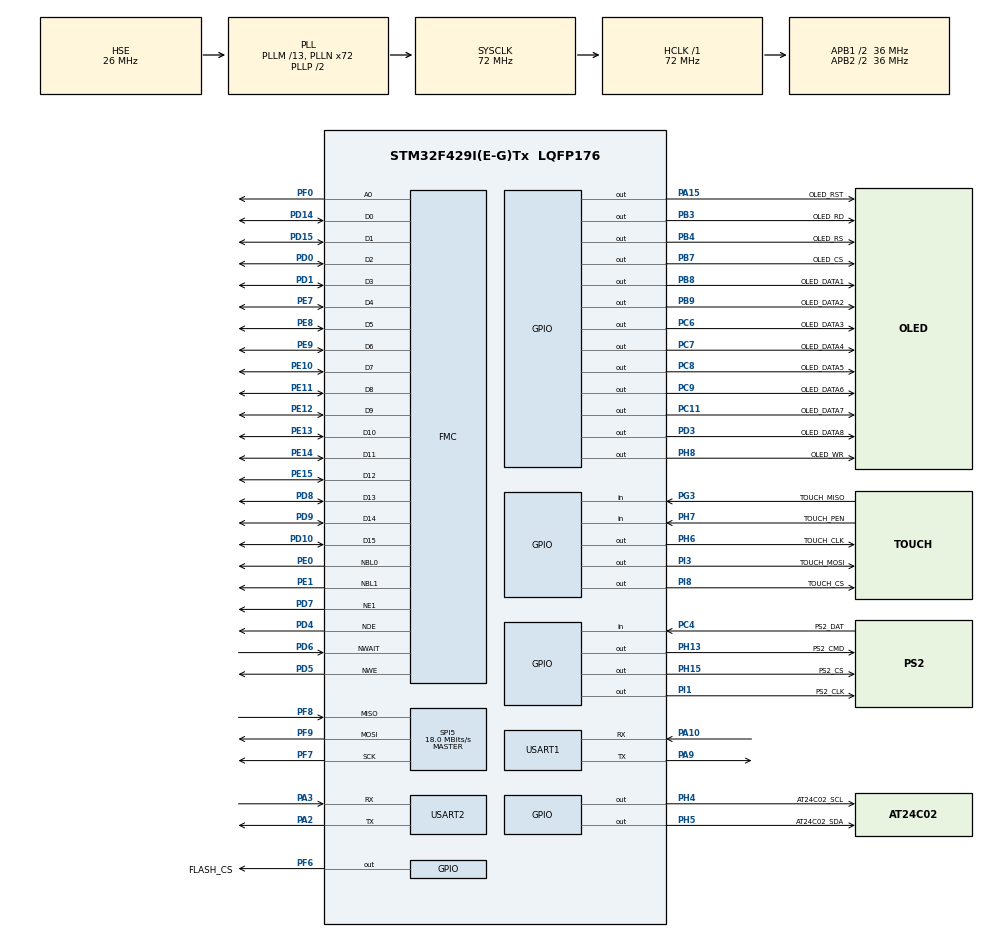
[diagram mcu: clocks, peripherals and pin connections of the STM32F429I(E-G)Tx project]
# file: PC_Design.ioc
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Dma.Request0=USART1_RX
Dma.Request1=USART1_TX
Dma.Request2=USART2_RX
Dma.Request3=USART2_TX
Dma.USART1_RX.0.Direction=DMA_PERIPH_TO_MEMORY
Dma.USART1_RX.0.FIFOMode=DMA_FIFOMODE_DISABLE
Dma.USART1_RX.0.Instance=DMA2_Stream2
Dma.USART1_RX.0.MemDataAlignment=DMA_MDATAALIGN_BYTE
Dma.USART1_RX.0.MemInc=DMA_MINC_ENABLE
Dma.USART1_RX.0.Mode=DMA_NORMAL
Dma.USART1_RX.0.PeriphDataAlignment=DMA_PDATAALIGN_BYTE
Dma.USART1_RX.0.PeriphInc=DMA_PINC_DISABLE
Dma.USART1_RX.0.Priority=DMA_PRIORITY_LOW
Dma.USART1_TX.1.Direction=DMA_MEMORY_TO_PERIPH
Dma.USART1_TX.1.FIFOMode=DMA_FIFOMODE_DISABLE
Dma.USART1_TX.1.Instance=DMA2_Stream7
Dma.USART1_TX.1.MemDataAlignment=DMA_MDATAALIGN_BYTE
Dma.USART1_TX.1.MemInc=DMA_MINC_ENABLE
Dma.USART1_TX.1.Mode=DMA_NORMAL
Dma.USART1_TX.1.PeriphDataAlignment=DMA_PDATAALIGN_BYTE
Dma.USART1_TX.1.PeriphInc=DMA_PINC_DISABLE
Dma.USART1_TX.1.Priority=DMA_PRIORITY_LOW
Dma.USART2_RX.2.Direction=DMA_PERIPH_TO_MEMORY
Dma.USART2_RX.2.FIFOMode=DMA_FIFOMODE_DISABLE
Dma.USART2_RX.2.Instance=DMA1_Stream5
Dma.USART2_RX.2.MemDataAlignment=DMA_MDATAALIGN_BYTE
Dma.USART2_RX.2.MemInc=DMA_MINC_ENABLE
Dma.USART2_RX.2.Mode=DMA_NORMAL
Dma.USART2_RX.2.PeriphDataAlignment=DMA_PDATAALIGN_BYTE
Dma.USART2_RX.2.PeriphInc=DMA_PINC_DISABLE
Dma.USART2_RX.2.Priority=DMA_PRIORITY_LOW
Dma.USART2_TX.3.Direction=DMA_MEMORY_TO_PERIPH
Dma.USART2_TX.3.FIFOMode=DMA_FIFOMODE_DISABLE
Dma.USART2_TX.3.Instance=DMA1_Stream6
Dma.USART2_TX.3.MemDataAlignment=DMA_MDATAALIGN_BYTE
Dma.USART2_TX.3.MemInc=DMA_MINC_ENABLE
Dma.USART2_TX.3.Mode=DMA_NORMAL
Dma.USART2_TX.3.PeriphDataAlignment=DMA_PDATAALIGN_BYTE
Dma.USART2_TX.3.PeriphInc=DMA_PINC_DISABLE
Dma.USART2_TX.3.Priority=DMA_PRIORITY_LOW
FREERTOS.INCLUDE_vTaskDelayUntil=1
FREERTOS.Tasks01=defaultTask,0,128,StartDefaultTask,Default,NULL,Dynamic,NULL,NULL
FREERTOS.configMAX_PRIORITIES=9
Mcu.Family=STM32F4
Mcu.Name=STM32F429I(E-G)Tx
Mcu.Package=LQFP176
NVIC.DMA1_Stream5_IRQn=true\:0\:0\:false\:false\:true\:true\:false\:true
NVIC.DMA1_Stream6_IRQn=true\:0\:0\:false\:false\:true\:true\:false\:true
NVIC.DMA2_Stream2_IRQn=true\:0\:0\:false\:false\:true\:true\:false\:true
NVIC.DMA2_Stream7_IRQn=true\:0\:0\:false\:false\:true\:true\:false\:true
NVIC.PriorityGroup=NVIC_PRIORITYGROUP_4
NVIC.TIM5_IRQn=true\:0\:0\:false\:false\:true\:true\:true\:true
NVIC.TIM7_IRQn=true\:0\:0\:false\:false\:true\:false\:false\:true
NVIC.TimeBase=TIM7_IRQn
NVIC.TimeBaseIP=TIM7
NVIC.USART1_IRQn=true\:5\:0\:true\:false\:true\:false\:true\:true
NVIC.USART2_IRQn=true\:5\:0\:true\:false\:true\:false\:true\:true
PA10.Mode=Asynchronous
PA10.Signal=USART1_RX
PA13.Mode=Serial_Wire
PA13.Signal=SYS_JTMS-SWDIO
PA14.Mode=Serial_Wire
PA14.Signal=SYS_JTCK-SWCLK
PA15.GPIO_Label=OLED_RST
PA15.GPIO_ModeDefaultOutputPP=GPIO_MODE_OUTPUT_PP
PA15.GPIO_PuPd=GPIO_PULLUP
PA15.GPIO_Speed=GPIO_SPEED_FREQ_HIGH
PA15.PinState=GPIO_PIN_RESET
PA15.Signal=GPIO_Output
PA2.Mode=Asynchronous
PA2.Signal=USART2_TX
PA3.Mode=Asynchronous
PA3.Signal=USART2_RX
PA9.Mode=Asynchronous
PA9.Signal=USART1_TX
PB3.GPIO_Label=OLED_RD
PB3.GPIO_PuPd=GPIO_PULLUP
PB3.GPIO_Speed=GPIO_SPEED_FREQ_HIGH
PB3.Signal=GPIO_Output
PB4.GPIO_Label=OLED_RS
PB4.GPIO_PuPd=GPIO_PULLUP
PB4.GPIO_Speed=GPIO_SPEED_FREQ_HIGH
PB4.Signal=GPIO_Output
PB7.GPIO_Label=OLED_CS
PB7.GPIO_PuPd=GPIO_PULLUP
PB7.GPIO_Speed=GPIO_SPEED_FREQ_HIGH
PB7.Signal=GPIO_Output
PB8.GPIO_Label=OLED_DATA1
PB8.GPIO_PuPd=GPIO_PULLUP
PB8.GPIO_Speed=GPIO_SPEED_FREQ_HIGH
PB8.Signal=GPIO_Output
PB9.GPIO_Label=OLED_DATA2
PB9.GPIO_PuPd=GPIO_PULLUP
PB9.GPIO_Speed=GPIO_SPEED_FREQ_HIGH
PB9.Signal=GPIO_Output
PC11.GPIO_Label=OLED_DATA7
PC11.GPIO_PuPd=GPIO_PULLUP
PC11.GPIO_Speed=GPIO_SPEED_FREQ_HIGH
PC11.Signal=GPIO_Output
PC4.GPIO_Label=PS2_DAT
PC4.GPIO_PuPd=GPIO_PULLDOWN
PC4.Signal=GPIO_Input
PC6.GPIO_Label=OLED_DATA3
PC6.GPIO_PuPd=GPIO_PULLUP
PC6.GPIO_Speed=GPIO_SPEED_FREQ_HIGH
PC6.Signal=GPIO_Output
PC7.GPIO_Label=OLED_DATA4
PC7.GPIO_PuPd=GPIO_PULLUP
PC7.GPIO_Speed=GPIO_SPEED_FREQ_HIGH
PC7.Signal=GPIO_Output
PC8.GPIO_Label=OLED_DATA5
PC8.GPIO_PuPd=GPIO_PULLUP
PC8.GPIO_Speed=GPIO_SPEED_FREQ_HIGH
PC8.Signal=GPIO_Output
PC9.GPIO_Label=OLED_DATA6
PC9.GPIO_PuPd=GPIO_PULLUP
PC9.GPIO_Speed=GPIO_SPEED_FREQ_HIGH
PC9.Signal=GPIO_Output
PD0.Signal=FMC_D2_DA2
PD1.Signal=FMC_D3_DA3
PD10.Signal=FMC_D15_DA15
PD14.Signal=FMC_D0_DA0
PD15.Signal=FMC_D1_DA1
PD3.GPIO_Label=OLED_DATA8
PD3.GPIO_PuPd=GPIO_PULLUP
PD3.GPIO_Speed=GPIO_SPEED_FREQ_HIGH
PD3.Signal=GPIO_Output
PD4.Signal=FMC_NOE
PD5.Signal=FMC_NWE
PD6.Signal=FMC_NWAIT
PD7.Mode=NorPsramChipSelect1_1
PD7.Signal=FMC_NE1
PD8.Signal=FMC_D13_DA13
PD9.Signal=FMC_D14_DA14
PE0.Signal=FMC_NBL0
PE1.Signal=FMC_NBL1
PE10.Signal=FMC_D7_DA7
PE11.Signal=FMC_D8_DA8
PE12.Signal=FMC_D9_DA9
PE13.Signal=FMC_D10_DA10
PE14.Signal=FMC_D11_DA11
PE15.Signal=FMC_D12_DA12
PE7.Signal=FMC_D4_DA4
PE8.Signal=FMC_D5_DA5
PE9.Signal=FMC_D6_DA6
PF0.Signal=FMC_A0
PF6.GPIO_Label=FLASH_CS
PF6.GPIO_Speed=GPIO_SPEED_FREQ_HIGH
PF6.Signal=GPIO_Output
PF7.Mode=Full_Duplex_Master
PF7.Signal=SPI5_SCK
PF8.Mode=Full_Duplex_Master
PF8.Signal=SPI5_MISO
PF9.Mode=Full_Duplex_Master
PF9.Signal=SPI5_MOSI
PG3.GPIO_Label=TOUCH_MISO
PG3.Signal=GPIO_Input
PH0/OSC_IN.Mode=HSE-External-Oscillator
PH0/OSC_IN.Signal=RCC_OSC_IN
PH1/OSC_OUT.Mode=HSE-External-Oscillator
PH1/OSC_OUT.Signal=RCC_OSC_OUT
PH13.GPIO_Label=PS2_CMD
PH13.Signal=GPIO_Output
PH15.GPIO_Label=PS2_CS
PH15.Signal=GPIO_Output
PH4.GPIO_Label=AT24C02_SCL
PH4.GPIO_PuPd=GPIO_PULLUP
PH4.GPIO_Speed=GPIO_SPEED_FREQ_HIGH
PH4.PinState=GPIO_PIN_SET
PH4.Signal=GPIO_Output
PH5.GPIO_Label=AT24C02_SDA
PH5.GPIO_PuPd=GPIO_PULLUP
PH5.GPIO_Speed=GPIO_SPEED_FREQ_HIGH
PH5.PinState=GPIO_PIN_SET
PH5.Signal=GPIO_Output
PH6.GPIO_Label=TOUCH_CLK
PH6.GPIO_PuPd=GPIO_PULLUP
PH6.GPIO_Speed=GPIO_SPEED_FREQ_HIGH
PH6.PinState=GPIO_PIN_RESET
PH6.Signal=GPIO_Output
PH7.GPIO_Label=TOUCH_PEN
PH7.Signal=GPIO_Input
PH8.GPIO_Label=OLED_WR
PH8.GPIO_PuPd=GPIO_PULLUP
PH8.GPIO_Speed=GPIO_SPEED_FREQ_HIGH
PH8.Signal=GPIO_Output
PI1.GPIO_Label=PS2_CLK
PI1.Signal=GPIO_Output
PI3.GPIO_Label=TOUCH_MOSI
PI3.GPIO_PuPd=GPIO_PULLUP
PI3.GPIO_Speed=GPIO_SPEED_FREQ_HIGH
PI3.Signal=GPIO_Output
PI8.GPIO_Label=TOUCH_CS
PI8.GPIO_ModeDefaultOutputPP=GPIO_MODE_OUTPUT_PP
PI8.GPIO_PuPd=GPIO_PULLUP
PI8.Signal=GPIO_Output
ProjectManager.HeapSize=0x200
ProjectManager.StackSize=0x400
ProjectManager.TargetToolchain=MDK-ARM V5.27
RCC.48MHZClocksFreq_Value=36000000
RCC.AHBFreq_Value=72000000
RCC.APB1CLKDivider=RCC_HCLK_DIV2
RCC.APB1Freq_Value=36000000
RCC.APB1TimFreq_Value=72000000
RCC.APB2CLKDivider=RCC_HCLK_DIV2
RCC.APB2Freq_Value=36000000
RCC.APB2TimFreq_Value=72000000
RCC.CortexFreq_Value=72000000
RCC.HCLKFreq_Value=72000000
RCC.HSE_VALUE=26000000
RCC.HSI_VALUE=16000000
RCC.LSE_VALUE=32768
RCC.PLLM=13
RCC.PLLN=72
RCC.PLLSourceVirtual=RCC_PLLSOURCE_HSE
RCC.SYSCLKFreq_VALUE=72000000
RCC.SYSCLKSource=RCC_SYSCLKSOURCE_PLLCLK
RCC.VCOOutputFreq_Value=144000000
SH.FMC_A0.0=FMC_A0,1b-a1
SH.FMC_D0_DA0.0=FMC_D0,16b-d1
SH.FMC_D10_DA10.0=FMC_D10,16b-d1
SH.FMC_D11_DA11.0=FMC_D11,16b-d1
SH.FMC_D12_DA12.0=FMC_D12,16b-d1
SH.FMC_D13_DA13.0=FMC_D13,16b-d1
SH.FMC_D14_DA14.0=FMC_D14,16b-d1
SH.FMC_D15_DA15.0=FMC_D15,16b-d1
SH.FMC_D1_DA1.0=FMC_D1,16b-d1
SH.FMC_D2_DA2.0=FMC_D2,16b-d1
SH.FMC_D3_DA3.0=FMC_D3,16b-d1
SH.FMC_D4_DA4.0=FMC_D4,16b-d1
SH.FMC_D5_DA5.0=FMC_D5,16b-d1
SH.FMC_D6_DA6.0=FMC_D6,16b-d1
SH.FMC_D7_DA7.0=FMC_D7,16b-d1
SH.FMC_D8_DA8.0=FMC_D8,16b-d1
SH.FMC_D9_DA9.0=FMC_D9,16b-d1
SH.FMC_NBL0.0=FMC_NBL0,2ByteEnable1
SH.FMC_NBL1.0=FMC_NBL1,2ByteEnable1
SH.FMC_NOE.0=FMC_NOE,Sram1
SH.FMC_NWAIT.0=FMC_NWAIT,AsynchronousWait1
SH.FMC_NWE.0=FMC_NWE,Sram1
SPI5.BaudRatePrescaler=SPI_BAUDRATEPRESCALER_2
SPI5.CLKPhase=SPI_PHASE_2EDGE
SPI5.CLKPolarity=SPI_POLARITY_HIGH
SPI5.CalculateBaudRate=18.0 MBits/s
SPI5.Direction=SPI_DIRECTION_2LINES
SPI5.Mode=SPI_MODE_MASTER
SPI5.VirtualType=VM_MASTER
TIM5.Prescaler=71
USART1.VirtualMode=VM_ASYNC
USART2.VirtualMode=VM_ASYNC
VP_FREERTOS_VS_CMSIS_V1.Mode=CMSIS_V1
VP_SYS_VS_tim7.Mode=TIM7
VP_TIM5_VS_ClockSourceINT.Mode=Internal
board=custom

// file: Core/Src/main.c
/* USER CODE BEGIN Header */
/**
  ******************************************************************************
  * @file           : main.c
  * @brief          : Main program body
  ******************************************************************************
  * @attention
  *
  * <h2><center>&copy; Copyright (c) 2021 STMicroelectronics.
  * All rights reserved.</center></h2>
  *
  * This software component is licensed by ST under BSD 3-Clause license,
  * the "License"; You may not use this file except in compliance with the
  * License. You may obtain a copy of the License at:
  *                        opensource.org/licenses/BSD-3-Clause
  *
  ******************************************************************************
  */
/* USER CODE END Header */
#include "main.h"
#include "cmsis_os.h"
#include "dma.h"
#include "spi.h"
#include "tim.h"
#include "usart.h"
#include "gpio.h"
#include "fmc.h"

/* USER CODE BEGIN Includes */
#include "System_Config.h"
/* USER CODE END Includes */

void SystemClock_Config(void);
void MX_FREERTOS_Init(void);

int main(void)
{

  /* MCU Configuration--------------------------------------------------------*/

  /* Reset of all peripherals, Initializes the Flash interface and the Systick. */
  HAL_Init();

  /* Configure the system clock */
  SystemClock_Config();

  /* Initialize all configured peripherals */
  MX_GPIO_Init();
  MX_DMA_Init();
//  MX_FMC_Init();
  MX_USART1_UART_Init();
  MX_USART2_UART_Init();
  MX_SPI5_Init();
  MX_TIM5_Init();
  /* USER CODE BEGIN 2 */
	System_Resource_Init();

  /* USER CODE END 2 */

  /* Call init function for freertos objects (in freertos.c) */
  MX_FREERTOS_Init();
  /* Start scheduler */
  osKernelStart();

  /* We should never get here as control is now taken by the scheduler */
  /* Infinite loop */
  while (1)
  {

  }
}

void SystemClock_Config(void)
{
  RCC_OscInitTypeDef RCC_OscInitStruct = {0};
  RCC_ClkInitTypeDef RCC_ClkInitStruct = {0};

  /** Configure the main internal regulator output voltage
  */
  __HAL_RCC_PWR_CLK_ENABLE();
  __HAL_PWR_VOLTAGESCALING_CONFIG(PWR_REGULATOR_VOLTAGE_SCALE3);
  /** Initializes the RCC Oscillators according to the specified parameters
  * in the RCC_OscInitTypeDef structure.
  */
  RCC_OscInitStruct.OscillatorType = RCC_OSCILLATORTYPE_HSE;
  RCC_OscInitStruct.HSEState = RCC_HSE_ON;
  RCC_OscInitStruct.PLL.PLLState = RCC_PLL_ON;
  RCC_OscInitStruct.PLL.PLLSource = RCC_PLLSOURCE_HSE;
  RCC_OscInitStruct.PLL.PLLM = 13;
  RCC_OscInitStruct.PLL.PLLN = 72;
  RCC_OscInitStruct.PLL.PLLP = RCC_PLLP_DIV2;
  RCC_OscInitStruct.PLL.PLLQ = 4;
  if (HAL_RCC_OscConfig(&RCC_OscInitStruct) != HAL_OK)
  {
    Error_Handler();
  }
  /** Initializes the CPU, AHB and APB buses clocks
  */
  RCC_ClkInitStruct.ClockType = RCC_CLOCKTYPE_HCLK|RCC_CLOCKTYPE_SYSCLK
                              |RCC_CLOCKTYPE_PCLK1|RCC_CLOCKTYPE_PCLK2;
  RCC_ClkInitStruct.SYSCLKSource = RCC_SYSCLKSOURCE_PLLCLK;
  RCC_ClkInitStruct.AHBCLKDivider = RCC_SYSCLK_DIV1;
  RCC_ClkInitStruct.APB1CLKDivider = RCC_HCLK_DIV2;
  RCC_ClkInitStruct.APB2CLKDivider = RCC_HCLK_DIV2;

  if (HAL_RCC_ClockConfig(&RCC_ClkInitStruct, FLASH_LATENCY_2) != HAL_OK)
  {
    Error_Handler();
  }
}

void HAL_TIM_PeriodElapsedCallback(TIM_HandleTypeDef *htim)
{
  if (htim->Instance == TIM7) {
    HAL_IncTick();
  }
}

void Error_Handler(void)
{
}

/************************ (C) COPYRIGHT STMicroelectronics *****END OF FILE****/

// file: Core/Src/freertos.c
/* USER CODE BEGIN Header */
/**
  ******************************************************************************
  * File Name          : freertos.c
  * Description        : Code for freertos applications
  ******************************************************************************
  * @attention
  *
  * <h2><center>&copy; Copyright (c) 2021 STMicroelectronics.
  * All rights reserved.</center></h2>
  *
  * This software component is licensed by ST under Ultimate Liberty license
  * SLA0044, the "License"; You may not use this file except in compliance with
  * the License. You may obtain a copy of the License at:
  *                             www.st.com/SLA0044
  *
  ******************************************************************************
  */
/* USER CODE END Header */

#include "FreeRTOS.h"
#include "task.h"
#include "main.h"
#include "cmsis_os.h"

osThreadId defaultTaskHandle;

void StartDefaultTask(void const * argument);

void MX_FREERTOS_Init(void); /* (MISRA C 2004 rule 8.1) */

/* GetIdleTaskMemory prototype (linked to static allocation support) */
void vApplicationGetIdleTaskMemory( StaticTask_t **ppxIdleTaskTCBBuffer, StackType_t **ppxIdleTaskStackBuffer, uint32_t *pulIdleTaskStackSize );

/* USER CODE BEGIN GET_IDLE_TASK_MEMORY */
static StaticTask_t xIdleTaskTCBBuffer;
static StackType_t xIdleStack[configMINIMAL_STACK_SIZE];

void vApplicationGetIdleTaskMemory( StaticTask_t **ppxIdleTaskTCBBuffer, StackType_t **ppxIdleTaskStackBuffer, uint32_t *pulIdleTaskStackSize )
{
  *ppxIdleTaskTCBBuffer = &xIdleTaskTCBBuffer;
  *ppxIdleTaskStackBuffer = &xIdleStack[0];
  *pulIdleTaskStackSize = configMINIMAL_STACK_SIZE;
  /* place for user code */
}
/* USER CODE END GET_IDLE_TASK_MEMORY */

void MX_FREERTOS_Init(void) {

  /* Create the thread(s) */
  /* definition and creation of defaultTask */
  osThreadDef(defaultTask, StartDefaultTask, osPriorityNormal, 0, 128);
  defaultTaskHandle = osThreadCreate(osThread(defaultTask), NULL);

}

void StartDefaultTask(void const * argument)
{
  /* USER CODE BEGIN StartDefaultTask */
  /* Infinite loop */
  for(;;)
  {
		vTaskDelete(NULL);
    osDelay(1);
  }
  /* USER CODE END StartDefaultTask */
}

/************************ (C) COPYRIGHT STMicroelectronics *****END OF FILE****/
